AUTOSAR XML (schema 4-0-3)
standard types defined: uint32, Boolean
package /AUTOSAR_Platform/DataConstrs
  range DC_Boolean: raw 0..1
package /ComponentTypes
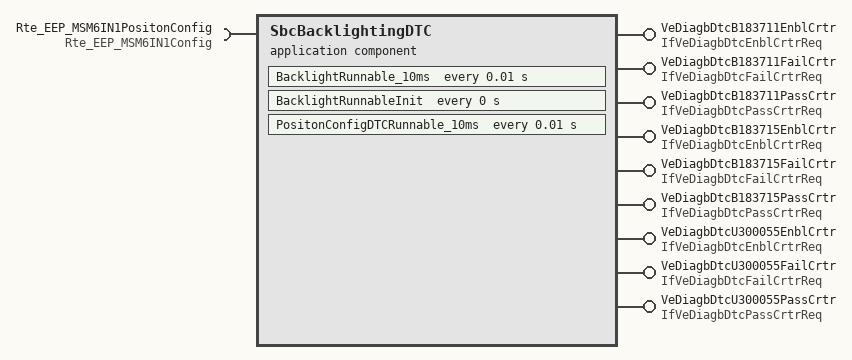
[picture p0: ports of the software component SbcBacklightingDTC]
  application sw component type SbcBacklightingDTC
    9 x provide port:
      VeDiagbDtcB183711EnblCrtr: nonqueued-sender-com-spec{data-element=IfVeDiagbDtcEnblCrtrReq/Val, init-value=0}, provided-interface=IfVeDiagbDtcEnblCrtrReq
      VeDiagbDtcB183711FailCrtr: nonqueued-sender-com-spec{data-element=IfVeDiagbDtcFailCrtrReq/Val, init-value=0}, provided-interface=IfVeDiagbDtcFailCrtrReq
      VeDiagbDtcB183711PassCrtr: nonqueued-sender-com-spec{data-element=IfVeDiagbDtcPassCrtrReq/Val, init-value=0}, provided-interface=IfVeDiagbDtcPassCrtrReq
      VeDiagbDtcB183715EnblCrtr: nonqueued-sender-com-spec{data-element=IfVeDiagbDtcEnblCrtrReq/Val, init-value=0}, provided-interface=IfVeDiagbDtcEnblCrtrReq
      VeDiagbDtcB183715FailCrtr: nonqueued-sender-com-spec{data-element=IfVeDiagbDtcFailCrtrReq/Val, init-value=0}, provided-interface=IfVeDiagbDtcFailCrtrReq
      VeDiagbDtcB183715PassCrtr: nonqueued-sender-com-spec{data-element=IfVeDiagbDtcPassCrtrReq/Val, init-value=0}, provided-interface=IfVeDiagbDtcPassCrtrReq
      VeDiagbDtcU300055EnblCrtr: nonqueued-sender-com-spec{data-element=IfVeDiagbDtcEnblCrtrReq/Val, init-value=0}, provided-interface=IfVeDiagbDtcEnblCrtrReq
      VeDiagbDtcU300055FailCrtr: nonqueued-sender-com-spec{data-element=IfVeDiagbDtcFailCrtrReq/Val, init-value=0}, provided-interface=IfVeDiagbDtcFailCrtrReq
      VeDiagbDtcU300055PassCrtr: nonqueued-sender-com-spec{data-element=IfVeDiagbDtcPassCrtrReq/Val, init-value=0}, provided-interface=IfVeDiagbDtcPassCrtrReq
    require port Rte_EEP_MSM6IN1PositonConfig: required-com-specs=[Get, Set], required-interface=Rte_EEP_MSM6IN1Config
    behavior SbcBacklightingDTC_InternalBehavior
      timing event TMT_BacklightRunnable_10ms: start-on-event=BacklightRunnable_10ms, period=0.01
      timing event Runnable_InitEvent: start-on-event=BacklightRunnableInit, period=0
      timing event TMT_Runnable: start-on-event=PositonConfigDTCRunnable_10ms, period=0.01
      runnable BacklightRunnable_10ms
        data-send-points:
          6 x access:
            SEND_VeDiagbDtcB183711EnblCrtr_Val: accessed-variable=VeDiagbDtcB183711EnblCrtr.Val
            SEND_VeDiagbDtcB183711FailCrtr_Val: accessed-variable=VeDiagbDtcB183711FailCrtr.Val
            SEND_VeDiagbDtcB183711PassCrtr_Val: accessed-variable=VeDiagbDtcB183711PassCrtr.Val
            SEND_VeDiagbDtcB183715EnblCrtr_Val: accessed-variable=VeDiagbDtcB183715EnblCrtr.Val
            SEND_VeDiagbDtcB183715FailCrtr_Val: accessed-variable=VeDiagbDtcB183715FailCrtr.Val
            SEND_VeDiagbDtcB183715PassCrtr_Val: accessed-variable=VeDiagbDtcB183715PassCrtr.Val
      runnable BacklightRunnableInit
      runnable PositonConfigDTCRunnable_10ms
        data-send-points:
          access SEND_VeDiagbDtcU300055EnblCrtr_Val: accessed-variable=VeDiagbDtcU300055EnblCrtr.Val
          access SEND_VeDiagbDtcU300055FailCrtr_Val: accessed-variable=VeDiagbDtcU300055FailCrtr.Val
          access SEND_VeDiagbDtcU300055PassCrtr_Val: accessed-variable=VeDiagbDtcU300055PassCrtr.Val
        sync call SC_Rte_EEP_MSM6IN1PositonConfig_Get: operation=Rte_EEP_MSM6IN1PositonConfig.Get, timeout=0
  swc implementation SbcBacklightingDTC_Implementation: behavior=SbcBacklightingDTC_InternalBehavior
    code-descriptors:
      code Default: artifact-descriptors=autosar-engineering-object={short-label=Default, category=SWSRC}
package /DataTypes
  impl type EEP_Uint32: category=VALUE, base-type=uint32, sw-calibration-access=READ-ONLY, type-emitter=RTE
package /PATAC/DIAG/DiagDataType
  sender receiver interface IfVeDiagbDtcEnblCrtrReq: invalidation-policy{data-element=IfVeDiagbDtcEnblCrtrReq/Val, handle-invalid=DONT-INVALIDATE}
    data Val: type=Boolean
  sender receiver interface IfVeDiagbDtcFailCrtrReq: invalidation-policy{data-element=IfVeDiagbDtcFailCrtrReq/Val, handle-invalid=DONT-INVALIDATE}
    data Val: type=Boolean
  sender receiver interface IfVeDiagbDtcPassCrtrReq: invalidation-policy{data-element=IfVeDiagbDtcPassCrtrReq/Val, handle-invalid=DONT-INVALIDATE}
    data Val: type=Boolean
package /PATAC/Facility/DataTypes/Implementation
  compu method COMPU_Boolean: 0=FALSE, 1=TRUE
  unit NoUnit: factor-si-to-unit=1, offset-si-to-unit=0
package /PortInterfaces
  client server interface Rte_EEP_MSM6IN1Config
    operation Get
      arg arg: type=EEP_Uint32, direction=OUT, server-argument-impl-policy=USE-ARGUMENT-TYPE
    operation Set
      arg arg: type=EEP_Uint32, direction=IN, server-argument-impl-policy=USE-ARGUMENT-TYPE
